# CH592SFR register map
Vendor: WCH Ltd.; Series: CH59x; File version: 1.0
CPU: RISC-V r0p0, little endian, no MPU, no FPU, 2 interrupt priority bits
Registers are 8-bit, Read or Write, reset 0x0 unless marked. A register's access mark holds for its fields unless they carry their own. Offsets are from the block's base; [hi:lo] are bit positions; {n}, {i} and the like mark numbered series.

## SYS — System Control Register
Base 0x40001000
0x08 R32_CLK_SYS_CFG 32-bit Read or Write under safe Accessing mode reset 0x140005 — RWA, system clock configuration, SAM
  [7:6] RB_CLK_SYS_MOD — RWA, system clock source mode: 00=divided from 32MHz
  [4:0] RB_CLK_PLL_DIV — RWA, output clock divider from PLL or CK32M
  [?] RB_XT_32M_PWR_EN — RWA, External 32MHz oscillator HSE power supply control 1: Power on, 0: Power off
  [?] RB_XT_FORCE_EN — RWA, Used to control the stop of the clock system in pause mode
  [?] RB_PLL_PWR_EN — RWA, PLL power control position
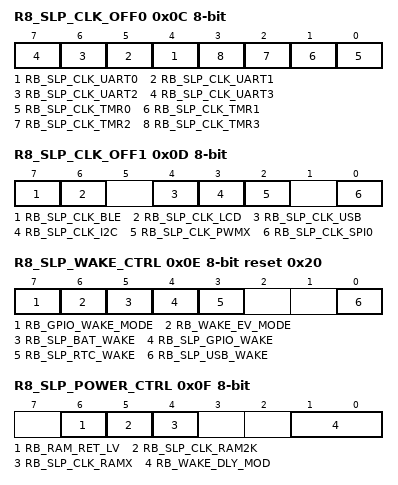
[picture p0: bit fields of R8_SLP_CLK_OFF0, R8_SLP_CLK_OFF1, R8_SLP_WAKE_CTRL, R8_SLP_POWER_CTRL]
0x0C R8_SLP_CLK_OFF0 Read or Write under safe Accessing mode — RWA, sleep clock off control byte 0, SAM
  [n+4] RB_SLP_CLK_UART{n} (n=0..3) — RWA, UART{n} clock source
  [n] RB_SLP_CLK_TMR{n} (n=0..3) — RWA, Timer {n} clock source
0x0D R8_SLP_CLK_OFF1 Read or Write under safe Accessing mode — RWA, sleep clock off control byte 1, SAM
  [7] RB_SLP_CLK_BLE — RWA, close BLE clock
  [6] RB_SLP_CLK_LCD — RWA, close LCD clock
  [4] RB_SLP_CLK_USB — RWA, close USB clock
  [3] RB_SLP_CLK_I2C — RWA, close I2C clock
  [2] RB_SLP_CLK_PWMX — RWA, close PWMx clock
  [0] RB_SLP_CLK_SPI0 — RWA, close SPI0 clock
0x0E R8_SLP_WAKE_CTRL Read or Write under safe Accessing mode reset 0x20 — RWA, wake control, SAM
  [7] RB_GPIO_WAKE_MODE — RWA, enable GPIO wake-up mode
  [6] RB_WAKE_EV_MODE — RWA, event wakeup mode
  [5] RB_SLP_BAT_WAKE — RWA, enable BAT waking
  [4] RB_SLP_GPIO_WAKE — RWA, enable GPIO waking
  [3] RB_SLP_RTC_WAKE — RWA, enable RTC waking
  [0] RB_SLP_USB_WAKE — RWA, enable USB waking
0x0F R8_SLP_POWER_CTRL Read or Write under safe Accessing mode — RWA, peripherals power down control, SAM
  [6] RB_RAM_RET_LV Read or  Write under safe Accessing mode — RWA, SRAM retention voltage selection
  [5] RB_SLP_CLK_RAM2K Read or  Write under safe Accessing mode — RWA, close retention 2KB SRAM clock
  [4] RB_SLP_CLK_RAMX Read or  Write under safe Accessing mode — RWA, close main SRAM clock
  [1:0] RB_WAKE_DLY_MOD Read or  Write under safe Accessing mode — RWA, wakeup delay time selection
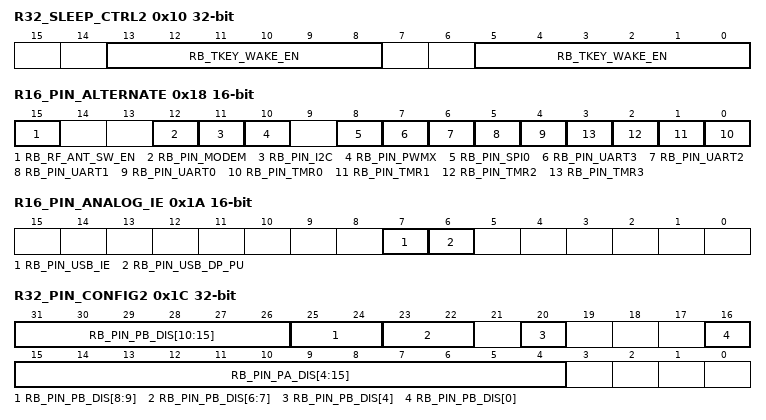
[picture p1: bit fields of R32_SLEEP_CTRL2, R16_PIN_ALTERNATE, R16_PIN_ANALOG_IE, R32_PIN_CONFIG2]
0x10 R32_SLEEP_CTRL2 32-bit Read or Write under safe Accessing mode — RWA, Sleep control register, SAM
  [13:8] RB_TKEY_WAKE_EN — RWA, Touch button wake-up enable: 1: On; 0: Close. Each digit corresponds to a button
  [5:0] RB_TKEY_WAKE_EN — RWA, Touch button wake-up enable: 1: On; 0: Close. Each digit corresponds to a button.
0x18 R16_PIN_ALTERNATE 16-bit — RW, function pin alternate configuration
  [15] RB_RF_ANT_SW_EN — RW, RF antenna switch control output enable
  [12] RB_PIN_MODEM — RW, DSR/DTR alternate pin enable
  [11] RB_PIN_I2C — RW, SCL/SDA alternate pin enable
  [10] RB_PIN_PWMX — RW, PWM4/PWM5/PWM7/PWM8/PWM9 alternate pin enable
  [8] RB_PIN_SPI0 — RW, SCS/SCK0/MOSI/MISO alternate pin enable
  [7] RB_PIN_UART3 — RW, RXD3/TXD3 alternate pin enable
  [6] RB_PIN_UART2 — RW, RXD2/TXD2 alternate pin enable
  [5] RB_PIN_UART1 Read or  Write — RW, RXD1/TXD1 alternate pin enable
  [4] RB_PIN_UART0 — RW, RXD0/TXD0 alternate pin enable
  [n] RB_PIN_TMR{n} (n=0..3) — RW, TMR{n} alternate pin enable
0x1A R16_PIN_ANALOG_IE 16-bit — RW, Analog pin enable and digital input disable
  [7] RB_PIN_USB_IE — RW, USB pin enable
  [6] RB_PIN_USB_DP_PU — RW, USB UD+pin internal pull-up resistor enable
0x1C R32_PIN_CONFIG2 32-bit — RW, Pin configuration register 2
  [31:26] RB_PIN_PB_DIS[10:15] — RW, PB10-PB15 channel pin digital input enable
  [25:24] RB_PIN_PB_DIS[8:9] — RW, PB22-PB23 channel pin digital input enable
  [23:22] RB_PIN_PB_DIS[6:7] — RW, PB6-PB7 channel pin digital input enable
  [20] RB_PIN_PB_DIS[4] — RW, PB4 channel pin digital input enable
  [16] RB_PIN_PB_DIS[0] — RW, PB0 channel pin digital input enable
  [15:4] RB_PIN_PA_DIS[4:15] — RW, PA4-PA15 channel pin digital input enable
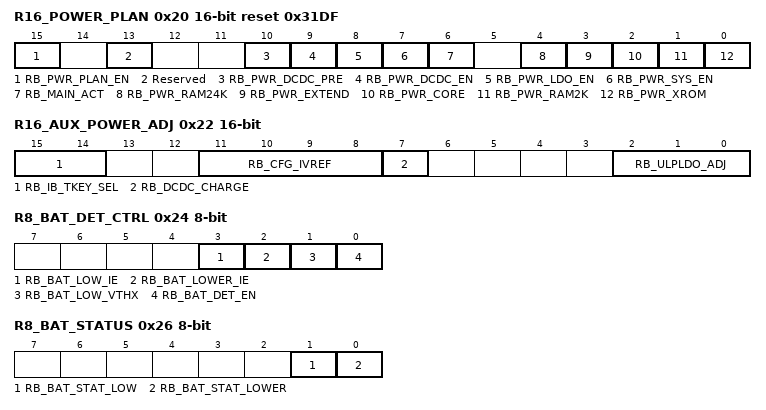
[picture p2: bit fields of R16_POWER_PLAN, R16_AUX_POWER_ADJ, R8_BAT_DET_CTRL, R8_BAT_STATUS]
0x20 R16_POWER_PLAN 16-bit Read or Write under safe Accessing mode reset 0x31DF — RWA, power plan before sleep instruction, SAM
  [15] RB_PWR_PLAN_EN — RWA, must write 0010
  [13] Reserved — RWA, retain. Must write 1.
  [10] RB_PWR_DCDC_PRE — RWA, DC/DC converter pre-enable
  [9] RB_PWR_DCDC_EN — RWA, DC/DC converter enable
  [8] RB_PWR_LDO_EN — RWA, Internal LDO control
  [7] RB_PWR_SYS_EN — RWA, power for system
  [6] RB_MAIN_ACT — RWA, Main power selection
  [4] RB_PWR_RAM24K — RWA, SRAM power supply for RAM24K
  [3] RB_PWR_EXTEND — RWA, power retention for USB and BLE
  [2] RB_PWR_CORE — RWA, power retention for core and base peripherals
  [1] RB_PWR_RAM2K — RWA, SRAM power supply for RAM2K
  [0] RB_PWR_XROM — RWA, power for FlashROM
0x22 R16_AUX_POWER_ADJ 16-bit Read or Write under safe Accessing mode reset not defined — RWA, aux power adjust control, SAM
  [15:14] RB_IB_TKEY_SEL — RWA, TouchKey bias current, used to stabilize I/O potential and prevent accidental wake-up
  [11:8] RB_CFG_IVREF — RWA, retain. The original value must be kept unchanged when writing
  [7] RB_DCDC_CHARGE — RWA, Low power auxiliary DC-DC enable bit
  [2:0] RB_ULPLDO_ADJ — RWA, Output voltage regulation value of auxiliary power supply for ultra-low power consumption LDO
0x24 R8_BAT_DET_CTRL Read or Write under safe Accessing mode — RWA, battery voltage detector control, SAM
  [3] RB_BAT_LOW_IE — RWA, interrupt enable for battery low voltage
  [2] RB_BAT_LOWER_IE — RWA, interrupt enable for battery lower voltage
  [1] RB_BAT_LOW_VTHX — RWA, When RB_BAT_MON_EN=1, set low power consumption
  [0] RB_BAT_DET_EN — RWA, When RB_BAT_MON_EN=0, it is enabled by high-precision battery voltage detection function
0x25 R8_BAT_DET_CFG Read or Write under safe Accessing mode reset 0x2 — RWA, battery voltage detector configuration, SAM
  [1:0] RB_BAT_LOW_VTH — RWA, select threshold voltage of battery voltage low
0x26 R8_BAT_STATUS ro — RO, battery status
  [1] RB_BAT_STAT_LOW — RO, battery low voltage status, high action
  [0] RB_BAT_STAT_LOWER — RO, battery lower voltage status, high action
0x2C R16_INT32K_TUNE 16-bit Read or Write under safe Accessing mode reset 0x1011 — RWA, internal 32KHz oscillator tune control, SAM
  [12:0] RB_INT32K_TUNE — RWA, internal 32KHz oscillator frequency tune
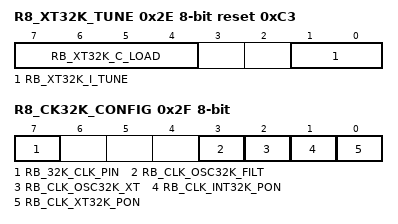
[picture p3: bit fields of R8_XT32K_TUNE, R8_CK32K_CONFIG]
0x2E R8_XT32K_TUNE Read or Write under safe Accessing mode reset 0xC3 — RWA, External 32KHz oscillator tune control, SAM
  [7:4] RB_XT32K_C_LOAD — RWA, External 32KHz oscillator load capacitor tune: Cap = RB_XT32K_C_LOAD + 12pF
  [1:0] RB_XT32K_I_TUNE — RWA, External 32KHz oscillator bias current selection
0x2F R8_CK32K_CONFIG Read or Write under safe Accessing mode reset not defined — RWA, 32KHz oscillator configure
  [7] RB_32K_CLK_PIN — RO, 32KHz oscillator clock pin status
  [3] RB_CLK_OSC32K_FILT — RWA, internal 32KHz oscillator low noise mode enable
  [2] RB_CLK_OSC32K_XT — RWA, 32KHz oscillator source selection: 0=RC, 1=XT
  [1] RB_CLK_INT32K_PON — RWA, internal 32KHz oscillator power on
  [0] RB_CLK_XT32K_PON — RWA, external 32KHz oscillator power on
